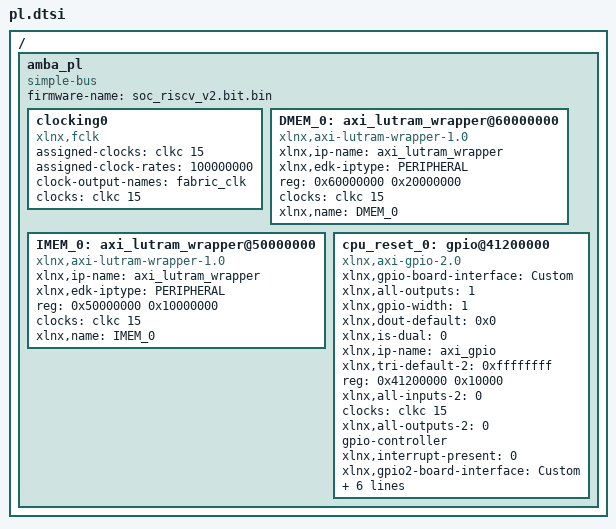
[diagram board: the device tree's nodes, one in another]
/ {
	amba_pl: amba_pl {
		ranges;
		compatible = "simple-bus";
		#address-cells = <1>;
		#size-cells = <1>;
		firmware-name = "soc_riscv_v2.bit.bin";
		clocking0: clocking0 {
			compatible = "xlnx,fclk";
			assigned-clocks = <&clkc 15>;
			assigned-clock-rates = <100000000>;
			#clock-cells = <0>;
			clock-output-names = "fabric_clk";
			clocks = <&clkc 15>;
		};
		DMEM_0: axi_lutram_wrapper@60000000 {
			compatible = "xlnx,axi-lutram-wrapper-1.0";
			status = "okay";
			clock-names = "S_AXI_ACLK";
			xlnx,ip-name = "axi_lutram_wrapper";
			xlnx,edk-iptype = "PERIPHERAL";
			reg = <0x60000000 0x20000000>;
			clocks = <&clkc 15>;
			xlnx,name = "DMEM_0";
		};
		IMEM_0: axi_lutram_wrapper@50000000 {
			compatible = "xlnx,axi-lutram-wrapper-1.0";
			status = "okay";
			clock-names = "S_AXI_ACLK";
			xlnx,ip-name = "axi_lutram_wrapper";
			xlnx,edk-iptype = "PERIPHERAL";
			reg = <0x50000000 0x10000000>;
			clocks = <&clkc 15>;
			xlnx,name = "IMEM_0";
		};
		cpu_reset_0: gpio@41200000 {
			xlnx,gpio-board-interface = "Custom";
			compatible = "xlnx,axi-gpio-2.0" , "xlnx,xps-gpio-1.00.a";
			xlnx,all-outputs = <1>;
			#gpio-cells = <2>;
			xlnx,gpio-width = <1>;
			xlnx,dout-default = <0x0>;
			xlnx,is-dual = <0>;
			xlnx,ip-name = "axi_gpio";
			xlnx,tri-default-2 = <0xffffffff>;
			reg = <0x41200000 0x10000>;
			xlnx,all-inputs-2 = <0>;
			clocks = <&clkc 15>;
			xlnx,all-outputs-2 = <0>;
			gpio-controller;
			xlnx,interrupt-present = <0>;
			xlnx,gpio2-board-interface = "Custom";
			xlnx,edk-iptype = "PERIPHERAL";
			xlnx,dout-default-2 = <0x0>;
			status = "okay";
			xlnx,gpio2-width = <32>;
			clock-names = "s_axi_aclk";
			xlnx,tri-default = <0xffffffff>;
			xlnx,name = "cpu_reset_0";
			xlnx,all-inputs = <0>;
		};
	};
};
